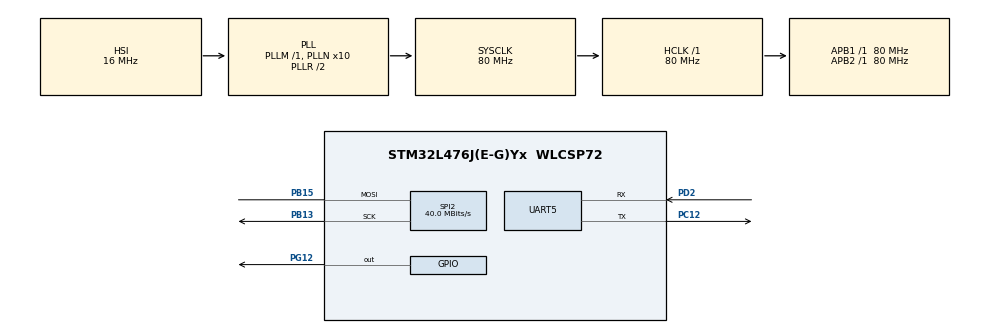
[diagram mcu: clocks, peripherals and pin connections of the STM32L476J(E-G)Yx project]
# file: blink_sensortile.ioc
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Mcu.Family=STM32L4
Mcu.Name=STM32L476J(E-G)Yx
Mcu.Package=WLCSP72
NVIC.PriorityGroup=NVIC_PRIORITYGROUP_4
PB13.Mode=Simplex_Bidirectional_Master
PB13.Signal=SPI2_SCK
PB15.Mode=Simplex_Bidirectional_Master
PB15.Signal=SPI2_MOSI
PC12.Mode=Asynchronous
PC12.Signal=UART5_TX
PD2.Mode=Asynchronous
PD2.Signal=UART5_RX
PG12.Signal=GPIO_Output
ProjectManager.HeapSize=0x200
ProjectManager.StackSize=0x400
ProjectManager.TargetToolchain=SW4STM32
RCC.ADCFreq_Value=64000000
RCC.AHBFreq_Value=80000000
RCC.APB1Freq_Value=80000000
RCC.APB1TimFreq_Value=80000000
RCC.APB2Freq_Value=80000000
RCC.APB2TimFreq_Value=80000000
RCC.CortexFreq_Value=80000000
RCC.HCLKFreq_Value=80000000
RCC.HSE_VALUE=8000000
RCC.HSI_VALUE=16000000
RCC.LSE_VALUE=32768
RCC.MSIAutoCalibration=DISABLED
RCC.MSI_VALUE=4000000
RCC.PLLN=10
RCC.PLLSourceVirtual=RCC_PLLSOURCE_HSI
RCC.SYSCLKFreq_VALUE=80000000
RCC.SYSCLKSource=RCC_SYSCLKSOURCE_PLLCLK
RCC.USBFreq_Value=64000000
RCC.VCOOutputFreq_Value=160000000
SPI2.CalculateBaudRate=40.0 MBits/s
SPI2.Direction=SPI_DIRECTION_1LINE
SPI2.Mode=SPI_MODE_MASTER
SPI2.VirtualType=VM_MASTER
STMicroelectronics.X-CUBE-MEMS1.6.2.0.BoardOoSupportJjSTM32CubeIiCustomIiBSPIiDrivers.apiComponent0=Board Extension\:IKS01A3
STMicroelectronics.X-CUBE-MEMS1.6.2.0.BoardOoSupportJjSTM32CubeIiCustomIiBSPIiDrivers.apiComponent1=Board Extension\:IKS01A2
STMicroelectronics.X-CUBE-MEMS1.6.2.0.BoardOoSupportJjSTM32CubeIiCustomIiBSPIiDrivers.apiDoc0=Documentation/X_CUBE_MEMS1.chm
STMicroelectronics.X-CUBE-MEMS1.6.2.0.BoardOoSupportJjSTM32CubeIiCustomIiBSPIiDrivers.apiDoc1=Documentation/X_CUBE_MEMS1.chm
STMicroelectronics.X-CUBE-MEMS1.6.2.0.BoardOoSupportJjSTM32CubeIiCustomIiBSPIiDrivers.cmp_version0=6.2.0
STMicroelectronics.X-CUBE-MEMS1.6.2.0.BoardOoSupportJjSTM32CubeIiCustomIiBSPIiDrivers.cmp_version1=6.2.0
STMicroelectronics.X-CUBE-MEMS1.6.2.0.BoardOoSupportJjSTM32CubeIiCustomIiBSPIiDrivers.component0=Board Support
STMicroelectronics.X-CUBE-MEMS1.6.2.0.BoardOoSupportJjSTM32CubeIiCustomIiBSPIiDrivers.component1=Board Support
STMicroelectronics.X-CUBE-MEMS1.6.2.0.BoardOoSupportJjSTM32CubeIiCustomIiBSPIiDrivers.description0=MEMS Board Support Package for custom boards,BSP for Motion Sensors 
STMicroelectronics.X-CUBE-MEMS1.6.2.0.BoardOoSupportJjSTM32CubeIiCustomIiBSPIiDrivers.description1=MEMS Board Support Package for custom boards,BSP for Environmental Sensors 
STMicroelectronics.X-CUBE-MEMS1.6.2.0.BoardOoSupportJjSTM32CubeIiCustomIiBSPIiDrivers.diagnostic0=This component requires one or more component from the same SW pack to operate correctly
STMicroelectronics.X-CUBE-MEMS1.6.2.0.BoardOoSupportJjSTM32CubeIiCustomIiBSPIiDrivers.diagnostic1=This component requires one or more component from the same SW pack to operate correctly
STMicroelectronics.X-CUBE-MEMS1.6.2.0.BoardOoSupportJjSTM32CubeIiCustomIiBSPIiDrivers.documentation0=Documentation/STMicroelectronics.X-CUBE-MEMS1_GettingStarted.pdf
STMicroelectronics.X-CUBE-MEMS1.6.2.0.BoardOoSupportJjSTM32CubeIiCustomIiBSPIiDrivers.documentation1=Documentation/STMicroelectronics.X-CUBE-MEMS1_GettingStarted.pdf
STMicroelectronics.X-CUBE-MEMS1.6.2.0.BoardOoSupportJjSTM32CubeIiCustomIiBSPIiDrivers.group0=Custom
STMicroelectronics.X-CUBE-MEMS1.6.2.0.BoardOoSupportJjSTM32CubeIiCustomIiBSPIiDrivers.group1=Custom
STMicroelectronics.X-CUBE-MEMS1.6.2.0.BoardOoSupportJjSTM32CubeIiCustomIiBSPIiDrivers.paramName0=STM32CubeIiCustomIiBSPIiDriversCcBoardOoSupportJjCustomJjMOTIONIiSENSOR
STMicroelectronics.X-CUBE-MEMS1.6.2.0.BoardOoSupportJjSTM32CubeIiCustomIiBSPIiDrivers.paramName1=STM32CubeIiCustomIiBSPIiDriversCcBoardOoSupportJjCustomJjENVIiSENSOR
STMicroelectronics.X-CUBE-MEMS1.6.2.0.BoardOoSupportJjSTM32CubeIiCustomIiBSPIiDrivers.sevirity0=minor
STMicroelectronics.X-CUBE-MEMS1.6.2.0.BoardOoSupportJjSTM32CubeIiCustomIiBSPIiDrivers.sevirity1=minor
STMicroelectronics.X-CUBE-MEMS1.6.2.0.BoardOoSupportJjSTM32CubeIiCustomIiBSPIiDrivers.sub-group0=MOTION_SENSOR
STMicroelectronics.X-CUBE-MEMS1.6.2.0.BoardOoSupportJjSTM32CubeIiCustomIiBSPIiDrivers.sub-group1=ENV_SENSOR
STMicroelectronics.X-CUBE-MEMS1.6.2.0.BoardOoSupportJjSTM32CubeIiCustomIiBSPIiDrivers_apiSize=2
STMicroelectronics.X-CUBE-MEMS1.6.2.0.BoardOoSupportJjSTM32CubeIiCustomIiBSPIiDrivers_bundle=STM32Cube_Custom_BSP_Drivers
STMicroelectronics.X-CUBE-MEMS1.6.2.0.BoardOoSupportJjSTM32CubeIiCustomIiBSPIiDrivers_class=BoardOoSupport
STMicroelectronics.X-CUBE-MEMS1.6.2.0.BoardOoSupportJjSTM32CubeIiCustomIiBSPIiDrivers_name=X-CUBE-MEMS1
STMicroelectronics.X-CUBE-MEMS1.6.2.0.BoardOoSupportJjSTM32CubeIiCustomIiBSPIiDrivers_size=2
STMicroelectronics.X-CUBE-MEMS1.6.2.0.BoardOoSupportJjSTM32CubeIiCustomIiBSPIiDrivers_vendor=STMicroelectronics
STMicroelectronics.X-CUBE-MEMS1.6.2.0.BoardOoSupportJjSTM32CubeIiCustomIiBSPIiDrivers_version=6.2.0
STMicroelectronics.X-CUBE-MEMS1.6.2.0.STM32CubeIiCustomIiBSPIiDriversCcBoardOoSupportJjCustomJjENVIiSENSOR=true
STMicroelectronics.X-CUBE-MEMS1.6.2.0.STM32CubeIiCustomIiBSPIiDriversCcBoardOoSupportJjCustomJjMOTIONIiSENSOR=true
STMicroelectronics.X-CUBE-MEMS1.6.2.0_BoardOoComponentJjMEMS_RteComponentsize=0
STMicroelectronics.X-CUBE-MEMS1.6.2.0_BoardOoExtensionJjMEMS_RteComponentsize=0
STMicroelectronics.X-CUBE-MEMS1.6.2.0_BoardOoSupportJjSTM32CubeIiCustomIiBSPIiDrivers_RteComponent0=\#define BSP_MOTION_SENSORS
STMicroelectronics.X-CUBE-MEMS1.6.2.0_BoardOoSupportJjSTM32CubeIiCustomIiBSPIiDrivers_RteComponent1=\#define BSP_ENV_SENSORS
STMicroelectronics.X-CUBE-MEMS1.6.2.0_BoardOoSupportJjSTM32CubeIiCustomIiBSPIiDrivers_RteComponentsize=2
STMicroelectronics.X-CUBE-MEMS1.6.2.0_DeviceJjApplication_RteComponentsize=0
STMicroelectronics.X-CUBE-MEMS1.6.2.0_description=Drivers and sample applications for MEMS components
STMicroelectronics.X-CUBE-MEMS1.6.2.0_license=en.DM00367782.pdf
VP_STMicroelectronics.X-CUBE-MEMS1_VS_BoardOoSupportJjSTM32CubeIiCustomIiBSPIiDrivers_6.2.0.Mode=BoardOoSupportJjSTM32CubeIiCustomIiBSPIiDrivers
board=custom

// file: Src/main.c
/* USER CODE BEGIN Header */
/**
  ******************************************************************************
  * @file           : main.c
  * @brief          : Main program body
  ******************************************************************************
  * @attention
  *
  * <h2><center>&copy; Copyright (c) 2019 STMicroelectronics.
  * All rights reserved.</center></h2>
  *
  * This software component is licensed by ST under BSD 3-Clause license,
  * the "License"; You may not use this file except in compliance with the
  * License. You may obtain a copy of the License at:
  *                        opensource.org/licenses/BSD-3-Clause
  *
  ******************************************************************************
  */
/* USER CODE END Header */

#include "main.h"
#include "SensorTile.h"
#include "SensorTile_motion_sensors.h"
#include "stdio.h"
#include "lsm6dsm.h"

SPI_HandleTypeDef hspi2;

UART_HandleTypeDef huart5;

void SystemClock_Config(void);
static void MX_GPIO_Init(void);
static void MX_SPI2_Init(void);
static void MX_UART5_Init(void);

/* USER CODE BEGIN 0 */

int __io_putchar(int ch)
{
	HAL_UART_Transmit(&huart5, (uint8_t *)&ch, 1, 0xFFFF);
	return ch;
}
/* USER CODE END 0 */

int main(void)
{
  /* USER CODE BEGIN 1 */
	float sensitivity;
  /* USER CODE END 1 */

  /* MCU Configuration--------------------------------------------------------*/

  /* Reset of all peripherals, Initializes the Flash interface and the Systick. */
  HAL_Init();

  /* Configure the system clock */
  SystemClock_Config();

  /* Initialize all configured peripherals */
  printf("Peripheral initialization\r\n");
  MX_GPIO_Init();
  MX_SPI2_Init();
  MX_UART5_Init();
  BSP_LED_Init(LED1);
  uint32_t Instances = 0;
  BSP_MOTION_SENSOR_Init(Instances, MOTION_ACCELERO);
  BSP_MOTION_SENSOR_SetFullScale(Instances,MOTION_ACCELERO,2);
  BSP_MOTION_SENSOR_GetSensitivity(Instances, MOTION_ACCELERO, &sensitivity);

  /* Infinite loop */
  /* USER CODE BEGIN WHILE */
  BSP_MOTION_SENSOR_AxesRaw_t accValues;

  while (1)
  {
    /* USER CODE END WHILE */
	  BSP_MOTION_SENSOR_GetAxesRaw(Instances, MOTION_ACCELERO, &accValues);
	  printf("x: %d\ty: %d\tz: %d\r\n",accValues.x,accValues.y,accValues.z);

	  BSP_LED_Toggle(LED1);
	  HAL_Delay(50);
  }
  /* USER CODE END 3 */
}

void SystemClock_Config(void)
{
  RCC_OscInitTypeDef RCC_OscInitStruct = {0};
  RCC_ClkInitTypeDef RCC_ClkInitStruct = {0};
  RCC_PeriphCLKInitTypeDef PeriphClkInit = {0};

  /** Initializes the CPU, AHB and APB busses clocks
  */
  RCC_OscInitStruct.OscillatorType = RCC_OSCILLATORTYPE_HSI;
  RCC_OscInitStruct.HSIState = RCC_HSI_ON;
  RCC_OscInitStruct.HSICalibrationValue = RCC_HSICALIBRATION_DEFAULT;
  RCC_OscInitStruct.PLL.PLLState = RCC_PLL_ON;
  RCC_OscInitStruct.PLL.PLLSource = RCC_PLLSOURCE_HSI;
  RCC_OscInitStruct.PLL.PLLM = 1;
  RCC_OscInitStruct.PLL.PLLN = 10;
  RCC_OscInitStruct.PLL.PLLP = RCC_PLLP_DIV7;
  RCC_OscInitStruct.PLL.PLLQ = RCC_PLLQ_DIV2;
  RCC_OscInitStruct.PLL.PLLR = RCC_PLLR_DIV2;
  if (HAL_RCC_OscConfig(&RCC_OscInitStruct) != HAL_OK)
  {
    Error_Handler();
  }
  /** Initializes the CPU, AHB and APB busses clocks
  */
  RCC_ClkInitStruct.ClockType = RCC_CLOCKTYPE_HCLK|RCC_CLOCKTYPE_SYSCLK
                              |RCC_CLOCKTYPE_PCLK1|RCC_CLOCKTYPE_PCLK2;
  RCC_ClkInitStruct.SYSCLKSource = RCC_SYSCLKSOURCE_PLLCLK;
  RCC_ClkInitStruct.AHBCLKDivider = RCC_SYSCLK_DIV1;
  RCC_ClkInitStruct.APB1CLKDivider = RCC_HCLK_DIV1;
  RCC_ClkInitStruct.APB2CLKDivider = RCC_HCLK_DIV1;

  if (HAL_RCC_ClockConfig(&RCC_ClkInitStruct, FLASH_LATENCY_4) != HAL_OK)
  {
    Error_Handler();
  }
  PeriphClkInit.PeriphClockSelection = RCC_PERIPHCLK_UART5;
  PeriphClkInit.Uart5ClockSelection = RCC_UART5CLKSOURCE_PCLK1;
  if (HAL_RCCEx_PeriphCLKConfig(&PeriphClkInit) != HAL_OK)
  {
    Error_Handler();
  }
  /** Configure the main internal regulator output voltage
  */
  if (HAL_PWREx_ControlVoltageScaling(PWR_REGULATOR_VOLTAGE_SCALE1) != HAL_OK)
  {
    Error_Handler();
  }
}

static void MX_SPI2_Init(void)
{

  /* SPI2 parameter configuration*/
  hspi2.Instance = SPI2;
  hspi2.Init.Mode = SPI_MODE_MASTER;
  hspi2.Init.Direction = SPI_DIRECTION_1LINE;
  hspi2.Init.DataSize = SPI_DATASIZE_4BIT;
  hspi2.Init.CLKPolarity = SPI_POLARITY_LOW;
  hspi2.Init.CLKPhase = SPI_PHASE_1EDGE;
  hspi2.Init.NSS = SPI_NSS_SOFT;
  hspi2.Init.BaudRatePrescaler = SPI_BAUDRATEPRESCALER_2;
  hspi2.Init.FirstBit = SPI_FIRSTBIT_MSB;
  hspi2.Init.TIMode = SPI_TIMODE_DISABLE;
  hspi2.Init.CRCCalculation = SPI_CRCCALCULATION_DISABLE;
  hspi2.Init.CRCPolynomial = 7;
  hspi2.Init.CRCLength = SPI_CRC_LENGTH_DATASIZE;
  hspi2.Init.NSSPMode = SPI_NSS_PULSE_ENABLE;
  if (HAL_SPI_Init(&hspi2) != HAL_OK)
  {
    Error_Handler();
  }

}

static void MX_UART5_Init(void)
{

  huart5.Instance = UART5;
  huart5.Init.BaudRate = 115200;
  huart5.Init.WordLength = UART_WORDLENGTH_8B;
  huart5.Init.StopBits = UART_STOPBITS_1;
  huart5.Init.Parity = UART_PARITY_NONE;
  huart5.Init.Mode = UART_MODE_TX_RX;
  huart5.Init.HwFlowCtl = UART_HWCONTROL_NONE;
  huart5.Init.OverSampling = UART_OVERSAMPLING_16;
  huart5.Init.OneBitSampling = UART_ONE_BIT_SAMPLE_DISABLE;
  huart5.AdvancedInit.AdvFeatureInit = UART_ADVFEATURE_NO_INIT;
  if (HAL_UART_Init(&huart5) != HAL_OK)
  {
    Error_Handler();
  }

}

static void MX_GPIO_Init(void)
{
  GPIO_InitTypeDef GPIO_InitStruct = {0};

  /* GPIO Ports Clock Enable */
  __HAL_RCC_GPIOD_CLK_ENABLE();
  __HAL_RCC_GPIOC_CLK_ENABLE();
  __HAL_RCC_GPIOG_CLK_ENABLE();
  HAL_PWREx_EnableVddIO2();
  __HAL_RCC_GPIOB_CLK_ENABLE();

  /*Configure GPIO pin Output Level */
 HAL_GPIO_WritePin(GPIOB, GPIO_PIN_12, GPIO_PIN_SET);

  /*Configure GPIO pin : PG12*/
  GPIO_InitStruct.Pin = GPIO_PIN_12;
  GPIO_InitStruct.Mode = GPIO_MODE_OUTPUT_PP;
  GPIO_InitStruct.Pull = GPIO_NOPULL;
  GPIO_InitStruct.Speed = GPIO_SPEED_FREQ_LOW;
  HAL_GPIO_Init(GPIOB, &GPIO_InitStruct);
  HAL_GPIO_WritePin(GPIOB, GPIO_PIN_12, GPIO_PIN_SET);

}

void Error_Handler(void)
{
}

/************************ (C) COPYRIGHT STMicroelectronics *****END OF FILE****/
